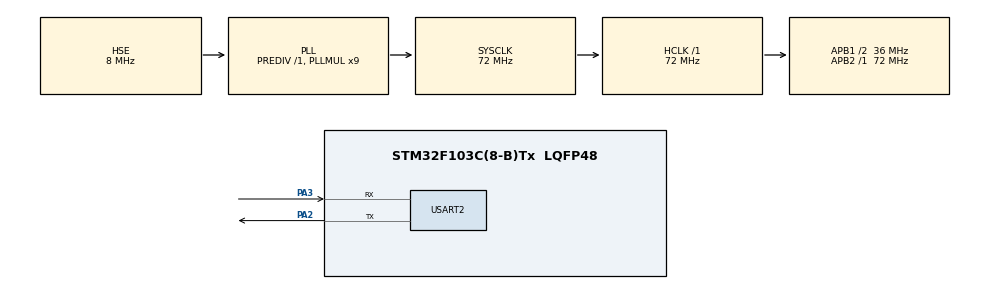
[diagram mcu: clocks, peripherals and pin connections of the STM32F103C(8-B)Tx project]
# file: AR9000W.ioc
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Dma.Request0=USART2_RX
Dma.USART2_RX.0.Direction=DMA_PERIPH_TO_MEMORY
Dma.USART2_RX.0.Instance=DMA1_Channel6
Dma.USART2_RX.0.MemDataAlignment=DMA_MDATAALIGN_BYTE
Dma.USART2_RX.0.MemInc=DMA_MINC_ENABLE
Dma.USART2_RX.0.Mode=DMA_NORMAL
Dma.USART2_RX.0.PeriphDataAlignment=DMA_PDATAALIGN_BYTE
Dma.USART2_RX.0.PeriphInc=DMA_PINC_DISABLE
Dma.USART2_RX.0.Priority=DMA_PRIORITY_LOW
Mcu.Family=STM32F1
Mcu.Name=STM32F103C(8-B)Tx
Mcu.Package=LQFP48
NVIC.DMA1_Channel6_IRQn=true\:0\:0\:false\:false\:true\:false\:true\:true
NVIC.PriorityGroup=NVIC_PRIORITYGROUP_4
NVIC.TIM2_IRQn=true\:0\:0\:false\:false\:true\:true\:true\:true
NVIC.USART2_IRQn=true\:0\:0\:false\:false\:true\:true\:true\:true
PA13.Mode=Serial_Wire
PA13.Signal=SYS_JTMS-SWDIO
PA14.Mode=Serial_Wire
PA14.Signal=SYS_JTCK-SWCLK
PA2.Mode=Asynchronous
PA2.Signal=USART2_TX
PA3.Mode=Asynchronous
PA3.Signal=USART2_RX
PD0-OSC_IN.Mode=HSE-External-Oscillator
PD0-OSC_IN.Signal=RCC_OSC_IN
PD1-OSC_OUT.Mode=HSE-External-Oscillator
PD1-OSC_OUT.Signal=RCC_OSC_OUT
ProjectManager.HeapSize=0x200
ProjectManager.StackSize=0x400
ProjectManager.TargetToolchain=MDK-ARM V5.32
RCC.AHBFreq_Value=72000000
RCC.APB1CLKDivider=RCC_HCLK_DIV2
RCC.APB1Freq_Value=36000000
RCC.APB1TimFreq_Value=72000000
RCC.APB2Freq_Value=72000000
RCC.APB2TimFreq_Value=72000000
RCC.HCLKFreq_Value=72000000
RCC.PLLMUL=RCC_PLL_MUL9
RCC.PLLSourceVirtual=RCC_PLLSOURCE_HSE
RCC.SYSCLKFreq_VALUE=72000000
RCC.SYSCLKSource=RCC_SYSCLKSOURCE_PLLCLK
RCC.USBFreq_Value=72000000
TIM2.Period=999
TIM2.Prescaler=71
USART2.VirtualMode=VM_ASYNC
VP_TIM2_VS_ClockSourceINT.Mode=Internal
board=custom

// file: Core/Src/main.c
/* USER CODE BEGIN Header */
/**
  ******************************************************************************
  * @file           : main.c
  * @brief          : Main program body
  ******************************************************************************
  * @attention
  *
  * Copyright (c) 2026 STMicroelectronics.
  * All rights reserved.
  *
  * This software is licensed under terms that can be found in the LICENSE file
  * in the root directory of this software component.
  * If no LICENSE file comes with this software, it is provided AS-IS.
  *
  ******************************************************************************
  */
/* USER CODE END Header */
#include "main.h"
#include "dma.h"
#include "tim.h"
#include "usart.h"
#include "gpio.h"

/* USER CODE BEGIN Includes */
#include "modbus.h"
#include "numled.h"
#include "key.h"
/* USER CODE END Includes */

void SystemClock_Config(void);

/* USER CODE BEGIN 0 */
BMS_Device_t bms_dev;
extern volatile uint8_t Soc_Flag;
/* USER CODE END 0 */
uint8_t flag = 0;
int main(void)
{

  /* MCU Configuration--------------------------------------------------------*/

  /* Reset of all peripherals, Initializes the Flash interface and the Systick. */
  HAL_Init();

  /* Configure the system clock */
  SystemClock_Config();

  /* Initialize all configured peripherals */
  MX_GPIO_Init();
  MX_DMA_Init();
  MX_USART2_UART_Init();
  MX_TIM2_Init();
  /* USER CODE BEGIN 2 */
  Num_Led_Init();
  Key_Init();
	HAL_Delay(5);
	HAL_TIM_Base_Start_IT(&htim2);
  /* USER CODE END 2 */

  /* Infinite loop */
  /* USER CODE BEGIN WHILE */

	/* ---- 1. 读取全部寄存器 ---- */
	LED_OFF;
  HAL_Delay(500);
	HAL_GPIO_WritePin(GPIO_Sleep_PORT, GPIO_Sleep_PIN, GPIO_PIN_RESET);// 拉低 → 复位
	HAL_Delay(300);

	HAL_GPIO_WritePin(GPIO_Sleep_PORT, GPIO_Sleep_PIN, GPIO_PIN_SET);// 拉高 → 释放
	HAL_Delay(500);
//	BMS_WriteRegister(1U, 0x0000U);
//	HAL_Delay(200);
//	BMS_WriteRegister(2U, 0x2000U);
//	HAL_Delay(500);
  BMS_ReadAll(&bms_dev);
  while (1)
  {
    /* USER CODE END WHILE */
    Key_Action();
		if(Soc_Flag){Soc_Show();}
  }
}

void SystemClock_Config(void)
{
  RCC_OscInitTypeDef RCC_OscInitStruct = {0};
  RCC_ClkInitTypeDef RCC_ClkInitStruct = {0};

  /** Initializes the RCC Oscillators according to the specified parameters
  * in the RCC_OscInitTypeDef structure.
  */
  RCC_OscInitStruct.OscillatorType = RCC_OSCILLATORTYPE_HSE;
  RCC_OscInitStruct.HSEState = RCC_HSE_ON;
  RCC_OscInitStruct.HSEPredivValue = RCC_HSE_PREDIV_DIV1;
  RCC_OscInitStruct.HSIState = RCC_HSI_ON;
  RCC_OscInitStruct.PLL.PLLState = RCC_PLL_ON;
  RCC_OscInitStruct.PLL.PLLSource = RCC_PLLSOURCE_HSE;
  RCC_OscInitStruct.PLL.PLLMUL = RCC_PLL_MUL9;
  if (HAL_RCC_OscConfig(&RCC_OscInitStruct) != HAL_OK)
  {
    Error_Handler();
  }

  /** Initializes the CPU, AHB and APB buses clocks
  */
  RCC_ClkInitStruct.ClockType = RCC_CLOCKTYPE_HCLK|RCC_CLOCKTYPE_SYSCLK
                              |RCC_CLOCKTYPE_PCLK1|RCC_CLOCKTYPE_PCLK2;
  RCC_ClkInitStruct.SYSCLKSource = RCC_SYSCLKSOURCE_PLLCLK;
  RCC_ClkInitStruct.AHBCLKDivider = RCC_SYSCLK_DIV1;
  RCC_ClkInitStruct.APB1CLKDivider = RCC_HCLK_DIV2;
  RCC_ClkInitStruct.APB2CLKDivider = RCC_HCLK_DIV1;

  if (HAL_RCC_ClockConfig(&RCC_ClkInitStruct, FLASH_LATENCY_2) != HAL_OK)
  {
    Error_Handler();
  }
}

/* USER CODE BEGIN 4 */
/**
  * @brief 定时器周期中断回调函数
  * 这个函数每1ms被自动调用一次
  */
void HAL_TIM_PeriodElapsedCallback(TIM_HandleTypeDef *htim)
{
  static uint8_t cnt = 0;
    if (htim->Instance == TIM2) {
        // 调用数码管扫描函数
        Led_under_deal();
        if(++cnt >= 10)           // 每10ms 执行一次按键扫描程序
        {
            Key_Scan();
            cnt = 0;
        }
    }
}
/* USER CODE END 4 */

void Error_Handler(void)
{
  __disable_irq();
  while (1)
  {
  }
}
